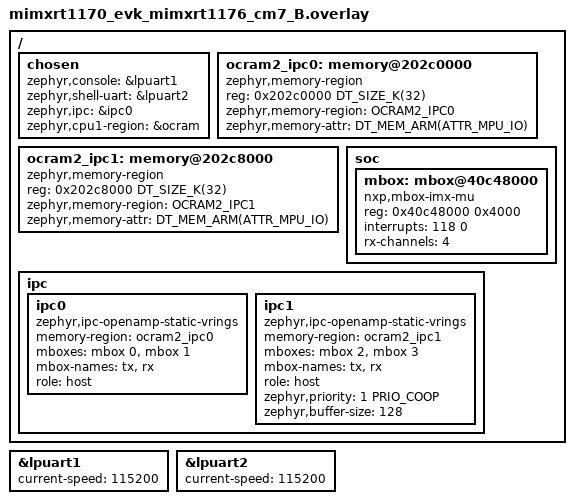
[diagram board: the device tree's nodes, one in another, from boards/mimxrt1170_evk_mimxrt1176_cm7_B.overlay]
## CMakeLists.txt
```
cmake_minimum_required(VERSION 3.20.0)
find_package(Zephyr REQUIRED HINTS $ENV{ZEPHYR_BASE})
project(cm7_shell)

if(CONFIG_INCLUDE_REMOTE_DIR)
  set(REMOTE_ZEPHYR_DIR ${CMAKE_CURRENT_BINARY_DIR}/../cm4_rpmsg/zephyr)
  target_include_directories(zephyr_interface
    INTERFACE ${REMOTE_ZEPHYR_DIR}/include/public)
endif()

if(CONFIG_SECOND_CORE_MCUX)
  set(REMOTE_ZEPHYR_DIR ${CMAKE_CURRENT_BINARY_DIR}/../cm4_rpmsg/zephyr)
  zephyr_include_directories(${REMOTE_ZEPHYR_DIR}/include/public)
endif()

target_sources(app PRIVATE
    src/main.c
    src/ipc_handler.c
    src/shell_cm4.c
    src/shell_ver.c
)
```

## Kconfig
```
# Copyright 2024 NXP
# SPDX-License-Identifier: Apache-2.0

source "Kconfig.zephyr"

config INCLUDE_REMOTE_DIR
    bool "Include remote core header directory"
    help
      Include remote build header files so primary image can find
      zephyr_image_info.h generated by the secondary core build.
```

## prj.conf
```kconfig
CONFIG_SHELL=y
CONFIG_SHELL_BACKEND_SERIAL=y
CONFIG_LOG=y
CONFIG_LOG_BACKEND_UART=y
CONFIG_LOG_CMDS=y
CONFIG_UART_CONSOLE=y
CONFIG_PRINTK=y
CONFIG_IPC_SERVICE=y
CONFIG_MBOX=y
CONFIG_OPENAMP=y
CONFIG_HEAP_MEM_POOL_SIZE=8192
CONFIG_MAIN_STACK_SIZE=4096
CONFIG_SYSTEM_WORKQUEUE_STACK_SIZE=4096
CONFIG_SHELL_STACK_SIZE=4096
CONFIG_SECOND_CORE_MCUX=y
CONFIG_INCLUDE_REMOTE_DIR=y

# SD Card and File System Support
CONFIG_DISK_DRIVERS=y
CONFIG_DISK_DRIVER_SDMMC=y
CONFIG_IMX_USDHC=y
CONFIG_FILE_SYSTEM=y
CONFIG_FAT_FILESYSTEM_ELM=y
CONFIG_FS_FATFS_LFN=y
CONFIG_FS_FATFS_EXFAT=y
CONFIG_FILE_SYSTEM_SHELL=y
```

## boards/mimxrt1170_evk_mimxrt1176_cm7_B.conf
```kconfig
CONFIG_MBOX_NXP_IMX_MU=y
CONFIG_BUILD_OUTPUT_HEX=y
```

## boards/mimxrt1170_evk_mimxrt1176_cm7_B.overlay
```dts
#include <zephyr/dt-bindings/ipc_service/static_vrings.h>
#include <zephyr/dt-bindings/memory-attr/memory-attr-arm.h>

/ {
    chosen {
        zephyr,console    = &lpuart1;
        zephyr,shell-uart = &lpuart2;
        /delete-property/ zephyr,ipc;
        /delete-property/ zephyr,ipc_shm;
        zephyr,ipc        = &ipc0;
        zephyr,cpu1-region = &ocram;
    };

    ocram2_ipc0: memory@202c0000 {
        compatible = "zephyr,memory-region", "mmio-sram";
        reg = <0x202c0000 DT_SIZE_K(32)>;
        zephyr,memory-region = "OCRAM2_IPC0";
        zephyr,memory-attr = <DT_MEM_ARM(ATTR_MPU_IO)>;
    };

    ocram2_ipc1: memory@202c8000 {
        compatible = "zephyr,memory-region", "mmio-sram";
        reg = <0x202c8000 DT_SIZE_K(32)>;
        zephyr,memory-region = "OCRAM2_IPC1";
        zephyr,memory-attr = <DT_MEM_ARM(ATTR_MPU_IO)>;
    };

    soc {
        /delete-node/ mailbox@40c48000;

        mbox: mbox@40c48000 {
            compatible = "nxp,mbox-imx-mu";
            reg = <0x40c48000 0x4000>;
            interrupts = <118 0>;
            rx-channels = <4>;
            #mbox-cells = <1>;
            status = "okay";
        };
    };

    ipc {
        /delete-node/ ipc0;

        ipc0: ipc0 {
            compatible = "zephyr,ipc-openamp-static-vrings";
            memory-region = <&ocram2_ipc0>;
            mboxes = <&mbox 0>, <&mbox 1>;
            mbox-names = "tx", "rx";
            role = "host";
            status = "okay";
        };

        ipc1: ipc1 {
            compatible = "zephyr,ipc-openamp-static-vrings";
            memory-region = <&ocram2_ipc1>;
            mboxes = <&mbox 2>, <&mbox 3>;
            mbox-names = "tx", "rx";
            role = "host";
            zephyr,priority = <1 PRIO_COOP>;
            zephyr,buffer-size = <128>;
            status = "okay";
        };
    };
};

&lpuart1 {
    status = "okay";
    current-speed = <115200>;
};

&lpuart2 {
    status = "okay";
    current-speed = <115200>;
};
```

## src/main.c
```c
#include <zephyr/kernel.h>
#include <zephyr/logging/log.h>
#include "ipc_handler.h"

LOG_MODULE_REGISTER(cm7_main, LOG_LEVEL_DBG);

static K_THREAD_STACK_DEFINE(ipc_stack, 2048);
static struct k_thread ipc_thread;

static void ipc_thread_entry(void *a, void *b, void *c)
{
    ipc_handler_init();
}

int main(void)
{
    LOG_INF("CM7 shell started on LPUART1");

    k_thread_create(&ipc_thread, ipc_stack,
                    K_THREAD_STACK_SIZEOF(ipc_stack),
                    ipc_thread_entry,
                    NULL, NULL, NULL,
                    K_PRIO_PREEMPT(5), 0, K_NO_WAIT);

    return 0;
}
```

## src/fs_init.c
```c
/*
 * fs_init.c - SD card auto-mount at boot
 */

#include <zephyr/kernel.h>
#include <zephyr/device.h>
#include <zephyr/storage/disk_access.h>
#include <zephyr/fs/fs.h>
#include <zephyr/logging/log.h>
#include <ff.h>

LOG_MODULE_REGISTER(fs_init, LOG_LEVEL_INF);

static FATFS fat_fs;
static struct fs_mount_t mp = {
    .type = FS_FATFS,
    .fs_data = &fat_fs,
};

/* Mount point */
static const char *sd_mount_point = "/SD:";

int fs_init(void)
{
    static const char *disk_name = "SD";
    int ret;

    LOG_INF("Initializing SD card file system...");

    /* Wait for SD card to be ready */
    ret = disk_access_init(disk_name);
    if (ret != 0) {
        LOG_ERR("SD card init failed: %d", ret);
        return ret;
    }

    mp.mnt_point = sd_mount_point;

    ret = fs_mount(&mp);
    if (ret != 0) {
        LOG_ERR("SD card mount failed: %d", ret);
        return ret;
    }

    LOG_INF("SD card mounted at %s", sd_mount_point);

    /* Create /SD:/recipes directory if it doesn't exist */
    ret = fs_mkdir("/SD:/recipes");
    if (ret == 0) {
        LOG_INF("Created /SD:/recipes directory");
    } else if (ret == -EEXIST) {
        LOG_INF("/SD:/recipes directory already exists");
    } else {
        LOG_WRN("Failed to create /SD:/recipes: %d", ret);
    }

    return 0;
}

/* Auto-initialize at boot */
SYS_INIT(fs_init, APPLICATION, CONFIG_APPLICATION_INIT_PRIORITY);
```

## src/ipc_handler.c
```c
#include <zephyr/kernel.h>
#include <zephyr/ipc/ipc_service.h>
#include <zephyr/logging/log.h>
#include <zephyr/shell/shell.h>
#include <string.h>
#include "ipc_handler.h"

LOG_MODULE_REGISTER(ipc_handler, LOG_LEVEL_DBG);

static struct ipc_ept ep;
static K_SEM_DEFINE(bound_sem, 0, 1);
static bool bound_once = false;

/* Shell pointer for printing CM4 responses */
static const struct shell *active_shell = NULL;
static K_SEM_DEFINE(resp_sem, 0, 1);

void ipc_handler_set_shell(const struct shell *sh)
{
    active_shell = sh;
}

static void ep_bound(void *priv)
{
    /* RPMsg backend fires bound twice (once per side) - only act on first */
    if (!bound_once) {
        bound_once = true;
        k_sem_give(&bound_sem);
    }
}

static void ep_recv(const void *data, size_t len, void *priv)
{
    if (len < sizeof(ipc_message_t)) {
        LOG_WRN("Short IPC message: %zu bytes", len);
        return;
    }

    const ipc_message_t *msg = (const ipc_message_t *)data;

    switch (msg->msg_type) {
    case IPC_MSG_TYPE_LOG:
        /* CM4 log message - print to CM7 console */
        LOG_INF("%s", msg->payload);
        break;

    case IPC_MSG_TYPE_RESP:
        /* Response to a shell command */
        if (active_shell) {
            shell_print(active_shell, "%s", msg->payload);
        } else {
            LOG_INF("CM4 resp: %s", msg->payload);
        }
        k_sem_give(&resp_sem);
        break;

    default:
        LOG_WRN("Unknown IPC msg type: 0x%02x", msg->msg_type);
        break;
    }
}

static struct ipc_ept_cfg ep_cfg = {
    .name = "cm4_ep",
    .cb = {
        .bound    = ep_bound,
        .received = ep_recv,
    },
};

int ipc_handler_init(void)
{
    const struct device *ipc_dev = DEVICE_DT_GET(DT_CHOSEN(zephyr_ipc));
    int ret;

    ret = ipc_service_open_instance(ipc_dev);
    if (ret < 0 && ret != -EALREADY) {
        LOG_ERR("ipc_service_open_instance failed: %d", ret);
        return ret;
    }

    ret = ipc_service_register_endpoint(ipc_dev, &ep, &ep_cfg);
    if (ret < 0) {
        LOG_ERR("ipc_service_register_endpoint failed: %d", ret);
        return ret;
    }

    LOG_INF("Waiting for CM4...");
    k_sem_take(&bound_sem, K_FOREVER);
    LOG_INF("IPC ready - CM4 is up");

    return 0;
}

int ipc_send_cmd(const char *cmd, size_t len)
{
    ipc_message_t msg = {0};

    msg.msg_type     = IPC_MSG_TYPE_CMD;
    msg.timestamp_ms = k_uptime_get_32();

    if (len >= sizeof(msg.payload)) {
        len = sizeof(msg.payload) - 1;
    }
    memcpy(msg.payload, cmd, len);
    msg.payload[len] = '\0';

    /* Clear any stale response semaphore */
    k_sem_reset(&resp_sem);

    int ret = ipc_service_send(&ep, &msg, sizeof(msg));
    if (ret < 0) {
        LOG_ERR("ipc_service_send failed: %d", ret);
        return ret;
    }

    /* Wait up to 2s for CM4 response */
    ret = k_sem_take(&resp_sem, K_MSEC(2000));
    if (ret == -EAGAIN) {
        if (active_shell) {
            shell_print(active_shell, "CM4 command timed out");
        }
        LOG_WRN("CM4 command response timeout");
    }

    return ret;
}
```

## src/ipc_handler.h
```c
#ifndef IPC_HANDLER_H
#define IPC_HANDLER_H

#include <stdint.h>
#include <stddef.h>
#include <zephyr/shell/shell.h>

/* Message types */
#define IPC_MSG_TYPE_LOG     0x01   /* CM4 -> CM7 */
#define IPC_MSG_TYPE_CMD     0x02   /* CM7 -> CM4 */
#define IPC_MSG_TYPE_RESP    0x03   /* CM4 -> CM7 */

#define IPC_MAX_PAYLOAD      220

typedef struct {
    uint8_t  msg_type;
    uint8_t  reserved[3];
    uint32_t timestamp_ms;
    char     payload[IPC_MAX_PAYLOAD];
} ipc_message_t;

/* CM7-side API */
int  ipc_handler_init(void);
int  ipc_send_cmd(const char *cmd, size_t len);
void ipc_handler_set_shell(const struct shell *sh);

#endif /* IPC_HANDLER_H */
```

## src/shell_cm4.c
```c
#include <zephyr/shell/shell.h>
#include <string.h>
#include "ipc_handler.h"

static int cmd_cm4(const struct shell *sh, size_t argc, char **argv)
{
    if (argc < 2) {
        shell_print(sh, "Usage: cm4 <command> [args...]");
        return 0;
    }

    /* Reconstruct command string from argv[1..] */
    char cmd_buf[IPC_MAX_PAYLOAD];
    size_t offset = 0;

    for (size_t i = 1; i < argc && offset < sizeof(cmd_buf) - 1; i++) {
        if (i > 1) {
            cmd_buf[offset++] = ' ';
        }
        size_t arglen = strlen(argv[i]);
        if (offset + arglen >= sizeof(cmd_buf) - 1) {
            arglen = sizeof(cmd_buf) - 1 - offset;
        }
        memcpy(cmd_buf + offset, argv[i], arglen);
        offset += arglen;
    }
    cmd_buf[offset] = '\0';

    ipc_handler_set_shell(sh);
    return ipc_send_cmd(cmd_buf, offset);
}

SHELL_CMD_ARG_REGISTER(cm4, NULL,
    "Send command to CM4 core\nUsage: cm4 <command> [args...]",
    cmd_cm4, 2, 8);
    
```

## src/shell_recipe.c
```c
/*
 * shell_recipe.c - PackTag recipe shell commands
 */

#include <zephyr/kernel.h>
#include <zephyr/shell/shell.h>
#include <zephyr/fs/fs.h>
#include <zephyr/logging/log.h>
#include <string.h>

#include "packtag_recipe.h"

LOG_MODULE_REGISTER(shell_recipe, LOG_LEVEL_INF);

static int cmd_recipe_save(const struct shell *sh, size_t argc, char **argv)
{
    if (argc != 2) {
        shell_error(sh, "Usage: recipe save <name>");
        return -EINVAL;
    }

    const char *name = argv[1];
    char path[64];
    snprintf(path, sizeof(path), "/SD:/recipes/%s.ini", name);

    shell_print(sh, "Saving recipe to %s...", path);

    PackRecipeResult_t result = PackTag_SaveRecipe(path, name);

    switch (result) {
        case RECIPE_OK:
            shell_print(sh, "Recipe saved successfully");
            return 0;
        case RECIPE_ERR_FILE_OPEN:
            shell_error(sh, "Failed to open file");
            return -EIO;
        case RECIPE_ERR_WRITE:
            shell_error(sh, "Failed to write file");
            return -EIO;
        case RECIPE_ERR_NOT_AVAILABLE:
            shell_error(sh, "File system not available");
            return -ENODEV;
        default:
            shell_error(sh, "Unknown error: %d", result);
            return -EIO;
    }
}

static int cmd_recipe_load(const struct shell *sh, size_t argc, char **argv)
{
    if (argc != 2) {
        shell_error(sh, "Usage: recipe load <name>");
        return -EINVAL;
    }

    const char *name = argv[1];
    char path[64];
    snprintf(path, sizeof(path), "/SD:/recipes/%s.ini", name);

    shell_print(sh, "Loading recipe from %s...", path);

    PackRecipeResult_t result = PackTag_LoadRecipe(path, name);

    switch (result) {
        case RECIPE_OK:
            shell_print(sh, "Recipe loaded successfully");
            return 0;
        case RECIPE_ERR_FILE_OPEN:
            shell_error(sh, "Failed to open file (does it exist?)");
            return -ENOENT;
        case RECIPE_ERR_FORMAT:
            shell_error(sh, "Invalid recipe format");
            return -EINVAL;
        case RECIPE_ERR_CRC_MISSING:
            shell_error(sh, "CRC field missing");
            return -EINVAL;
        case RECIPE_ERR_CRC_FAIL:
            shell_error(sh, "CRC verification failed");
            return -EILSEQ;
        case RECIPE_ERR_UNKNOWN_KEY:
            shell_error(sh, "Unknown parameter key in file");
            return -EINVAL;
        case RECIPE_ERR_NOT_AVAILABLE:
            shell_error(sh, "File system not available");
            return -ENODEV;
        default:
            shell_error(sh, "Unknown error: %d", result);
            return -EIO;
    }
}

static int cmd_recipe_list(const struct shell *sh, size_t argc, char **argv)
{
    struct fs_dir_t dir;
    struct fs_dirent entry;
    int ret;

    fs_dir_t_init(&dir);

    ret = fs_opendir(&dir, "/SD:/recipes");
    if (ret != 0) {
        shell_error(sh, "Failed to open /SD:/recipes: %d", ret);
        return ret;
    }

    shell_print(sh, "Available recipes:");
    shell_print(sh, "% -30s %10s", "Name", "Size");
    shell_print(sh, "----------------------------------------");

    while (1) {
        ret = fs_readdir(&dir, &entry);
        if (ret != 0 || entry.name[0] == 0) {
            break;
        }

        if (entry.type == FS_DIR_ENTRY_FILE) {
            /* Only show .ini files */
            size_t len = strlen(entry.name);
            if (len > 4 && strcmp(&entry.name[len - 4], ".ini") == 0) {
                shell_print(sh, "%-30s %10zu", entry.name, entry.size);
            }
        }
    }

    fs_closedir(&dir);
    return 0;
}

SHELL_STATIC_SUBCMD_SET_CREATE(recipe_cmds,
    SHELL_CMD(save, NULL, "Save current parameters to recipe", cmd_recipe_save),
    SHELL_CMD(load, NULL, "Load recipe parameters", cmd_recipe_load),
    SHELL_CMD(list, NULL, "List available recipes", cmd_recipe_list),
    SHELL_SUBCMD_SET_END
);

SHELL_CMD_REGISTER(recipe, &recipe_cmds, "PackTag recipe commands", NULL);
```

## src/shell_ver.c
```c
#include <zephyr/kernel.h>
#include <zephyr/shell/shell.h>
#include <zephyr/device.h>
#include "ipc_handler.h"

#define FW_VERSION      "0.1.0"
#define BOARD_NAME      "MIMXRT1170-EVK Rev B"

/* ver - show CM7 firmware info */
static int cmd_ver(const struct shell *sh, size_t argc, char **argv)
{
    shell_print(sh, "Board:   %s", BOARD_NAME);
    shell_print(sh, "FW Ver:  %s", FW_VERSION);
    shell_print(sh, "Built:   %s %s", __DATE__, __TIME__);
    shell_print(sh, "CM7 uptime: %u ms", k_uptime_get_32());
    return 0;
}

/* shendpts - show IPC endpoint info */
static int cmd_shendpts(const struct shell *sh, size_t argc, char **argv)
{
    const struct device *ipc_dev = DEVICE_DT_GET(DT_CHOSEN(zephyr_ipc));
    shell_print(sh, "CM7 IPC device: %s", ipc_dev->name);
    shell_print(sh, "IPC shared mem: OCRAM2_IPC0 @ 0x202C0000 (32KB)");
    shell_print(sh, "IPC shared mem: OCRAM2_IPC1 @ 0x202C8000 (32KB)");
    shell_print(sh, "Use 'cm4 shendpts' to show CM4-side endpoint info");
    return 0;
}

/* ipcecho - send a message to CM4 and get it echoed back */
static int cmd_ipcecho(const struct shell *sh, size_t argc, char **argv)
{
    if (argc < 2) {
        shell_print(sh, "Usage: ipcecho <message>");
        return 0;
    }

    /* Build message string */
    char buf[IPC_MAX_PAYLOAD];
    size_t offset = 0;

    /* Prefix with "echo " so CM4 cmd_dispatch routes it */
    offset += snprintf(buf, sizeof(buf), "echo ");

    for (size_t i = 1; i < argc && offset < sizeof(buf) - 1; i++) {
        if (i > 1) {
            buf[offset++] = ' ';
        }
        size_t arglen = strlen(argv[i]);
        if (offset + arglen >= sizeof(buf) - 1) {
            arglen = sizeof(buf) - 1 - offset;
        }
        memcpy(buf + offset, argv[i], arglen);
        offset += arglen;
    }
    buf[offset] = '\0';

    ipc_handler_set_shell(sh);
    return ipc_send_cmd(buf, offset);
}

SHELL_CMD_ARG_REGISTER(ver,      NULL, "Display firmware version info",           cmd_ver,      1, 0);
SHELL_CMD_ARG_REGISTER(shendpts, NULL, "Show IPC endpoint addresses",             cmd_shendpts, 1, 0);
SHELL_CMD_ARG_REGISTER(ipcecho,  NULL, "Echo a message via CM4 IPC\n"
                                       "Usage: ipcecho <message>",                cmd_ipcecho,  2, 8);
```
